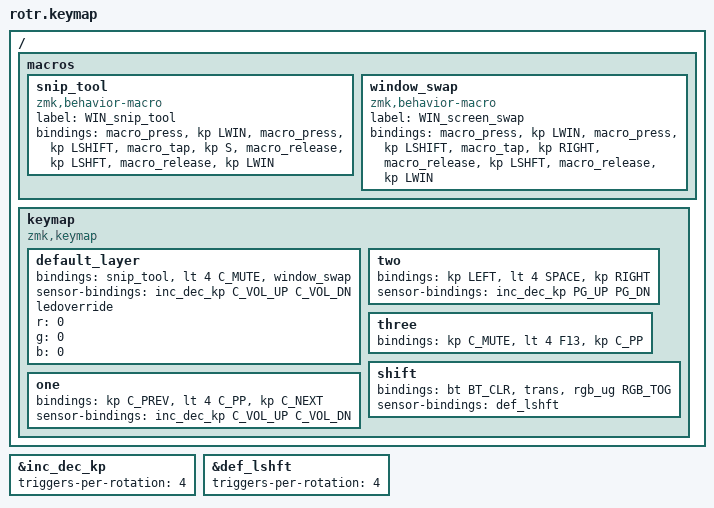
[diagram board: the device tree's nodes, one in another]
#include <behaviors.dtsi>
#include <dt-bindings/zmk/keys.h>
#include <dt-bindings/zmk/rgb.h>
#include <dt-bindings/zmk/bt.h>

&inc_dec_kp {
	triggers-per-rotation = <4>;
};
&def_lshft {
	triggers-per-rotation = <4>;
};

/ {
	macros {
		snip_tool: snip_tool {
		    label = "WIN_snip_tool";
		    compatible = "zmk,behavior-macro";
		    #binding-cells = <0>;
		    bindings
			= <&macro_press &kp LWIN>
			, <&macro_press &kp LSHIFT >
			, <&macro_tap &kp S >
			, <&macro_release &kp LSHFT>
			, <&macro_release &kp LWIN>
			;
		};
		window_swap: window_swap {
		    label = "WIN_screen_swap";
		    compatible = "zmk,behavior-macro";
		    #binding-cells = <0>;
		    bindings
			= <&macro_press &kp LWIN>
			, <&macro_press &kp LSHIFT >
			, <&macro_tap &kp RIGHT >
			, <&macro_release &kp LSHFT>
			, <&macro_release &kp LWIN>
			;
		};
	    };
	keymap {
	
		compatible = "zmk,keymap";

		default_layer {
			// WIN+SHIFT+LEFT | MUTE/UNMUTE | WIN+SHIFT+R
			bindings = <&snip_tool &lt 4 C_MUTE &window_swap>;
			sensor-bindings = <&inc_dec_kp C_VOL_UP C_VOL_DN>;
			ledoverride;
			r = <0>;
			g = <0>;
			b = <0>;
		};
		one {
			//PREV | PLAY/PAUSE | NEXT
			bindings = <&kp C_PREV &lt 4 C_PP &kp C_NEXT>;
			sensor-bindings = <&inc_dec_kp C_VOL_UP C_VOL_DN>;
		};
		two {
			//PREV | PLAY/PAUSE | NEXT
			bindings = <&kp LEFT &lt 4 SPACE &kp RIGHT>;
			sensor-bindings = <&inc_dec_kp PG_UP PG_DN>;
		};
		three {
			//PREV | PLAY/PAUSE | NEXT
			bindings = <&kp C_MUTE &lt 4 F13 &kp C_PP>;
		};
		shift {
			//PREV | PLAY/PAUSE | NEXT
			bindings = <&bt BT_CLR &trans &rgb_ug RGB_TOG>;
			sensor-bindings = <&def_lshft>;
		};
	};
};
